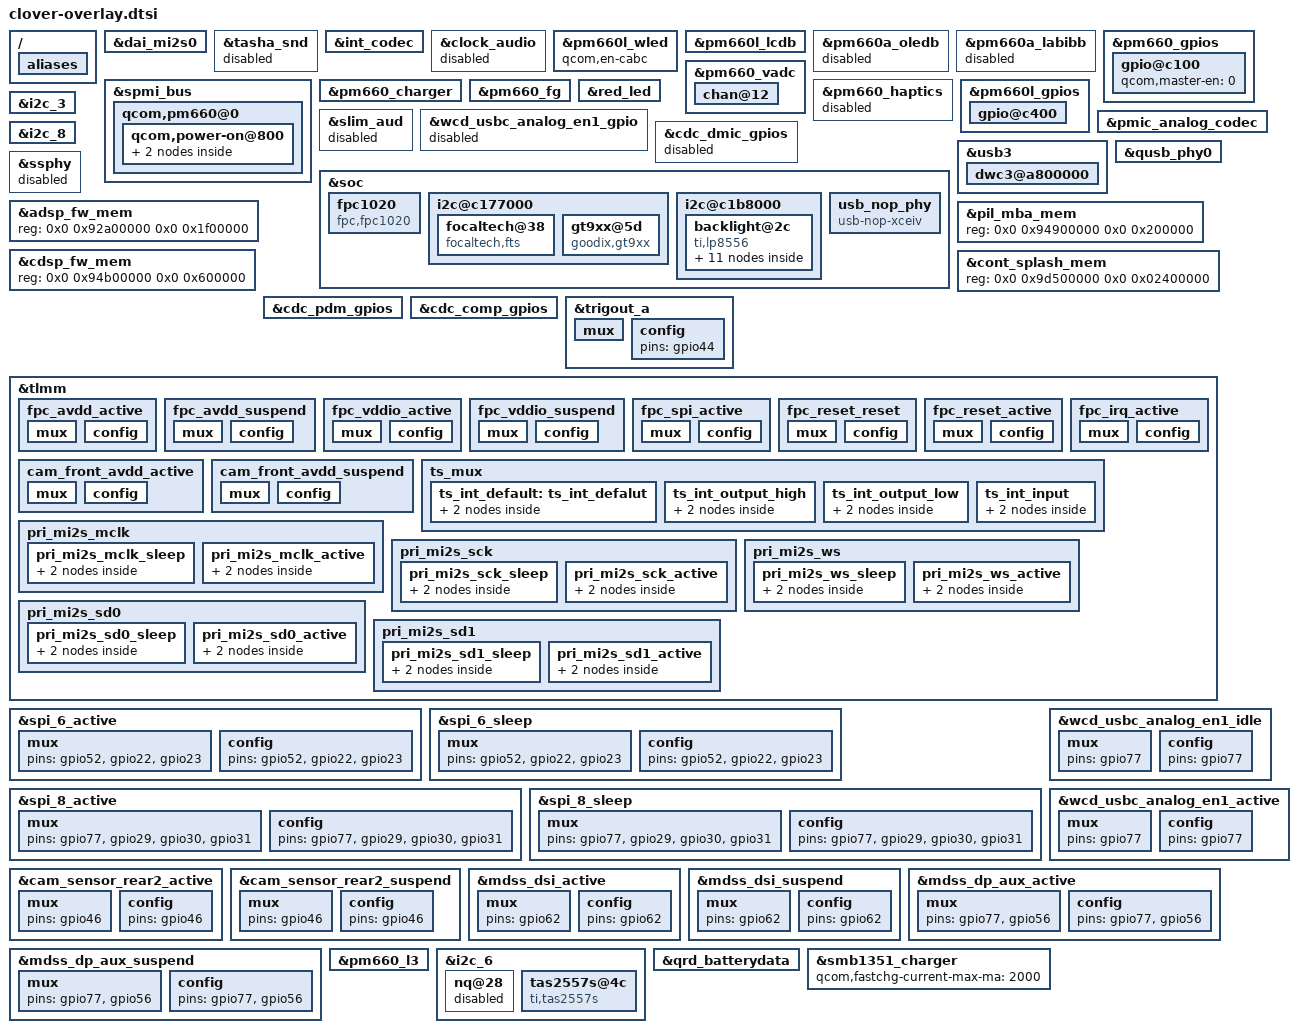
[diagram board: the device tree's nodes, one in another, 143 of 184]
&dai_mi2s0 {
	qcom,msm-mi2s-rx-lines = <1>;
	qcom,msm-mi2s-tx-lines = <2>;
	pinctrl-names = "default", "sleep";
	pinctrl-0 = <&pri_mi2s_mclk_active
		&pri_mi2s_sck_active
		&pri_mi2s_ws_active
		&pri_mi2s_sd0_active
		&pri_mi2s_sd1_active>;
	pinctrl-1 = <&pri_mi2s_mclk_sleep
		&pri_mi2s_sck_sleep
		&pri_mi2s_ws_sleep
		&pri_mi2s_sd0_sleep
		&pri_mi2s_sd1_sleep>;
};

&tasha_snd {
	status="disabled";
};
/*
&tavil_snd {
	status="disabled";
};
*/
&int_codec {
	/delete-property/ qcom,msm-micbias2-ext-cap;
	status="okay";
	qcom,wsa-disable;
	qcom,msm-mi2s-ext-mclk = <1>, <0>, <0>, <0>;
	qcom,msm-mbhc-gnd-swh = <0>;
	qcom,msm-micbias1-ext-cap;
	qcom,msm-hs-micbias-type = "internal";
	qcom,audio-routing =
		"RX_BIAS", "INT_MCLK0",
		"SPK_RX_BIAS", "INT_MCLK0",
		"INT_LDO_H", "INT_MCLK0",
		"RX_I2S_CLK", "INT_MCLK0",
		"TX_I2S_CLK", "INT_MCLK0",
		"MIC BIAS External", "Handset Mic",
		"MIC BIAS External2", "Headset Mic",
		"MIC BIAS Internal2", "Headset Mic",
		"MIC BIAS External", "Secondary Mic",
		"AMIC1", "MIC BIAS External",
		"AMIC2", "MIC BIAS External2",
		"AMIC2", "MIC BIAS Internal2",
		"AMIC3", "MIC BIAS External",
		"DMIC1", "MIC BIAS External",
		"MIC BIAS External", "Digital Mic1",
		"DMIC2", "MIC BIAS External",
		"MIC BIAS External", "Digital Mic2",
		"DMIC3", "MIC BIAS External",
		"MIC BIAS External", "Digital Mic3",
		"DMIC4", "MIC BIAS External",
		"MIC BIAS External", "Digital Mic4",
		"SpkrLeft IN", "SPK1 OUT",
		"SpkrRight IN", "SPK2 OUT",
		"PDM_IN_RX1", "PDM_OUT_RX1",
		"PDM_IN_RX2", "PDM_OUT_RX2",
		"PDM_IN_RX3", "PDM_OUT_RX3",
		"ADC1_IN", "ADC1_OUT",
		"ADC2_IN", "ADC2_OUT",
		"ADC3_IN", "ADC3_OUT";
};

&clock_audio {
	status="disabled";
};

&pm660l_wled {
	status = "okay";
};

&pm660l_lcdb {
	status = "okay";
};

&pm660a_oledb {
	status = "disabled";
};

&pm660a_labibb {
	status = "disable";
};

&spmi_bus {
	qcom,pm660@0 {
		qcom,power-on@800 {
			qcom,pon_1 {
				qcom,support-reset = <1>;
				qcom,s1-timer = <6720>;
				qcom,s2-timer = <1000>;
				qcom,s2-type = <7>;
			};
			qcom,pon_3 {
				qcom,pon-type = <3>;
				qcom,support-reset = <1>;
				qcom,pull-up = <1>;
				qcom,s1-timer = <3072>;
				qcom,s2-timer = <2000>;
				qcom,s2-type = <1>;
				qcom,use-bark;
			};
		};
	};
};

&pm660_gpios {
	gpio@c100 {
		status = "okay";
		qcom,master-en = <0>; /* DISABLE GPIO */
	};
};

&pm660_vadc {
	chan@12 {
		label = "gpio2_adc";
		reg = <0x12>;
		qcom,decimation = <2>;
		qcom,pre-div-channel-scaling = <0>;
		qcom,calibration-type = "absolute";
		qcom,scale-function = <0>; /*use default scale fuction, liyan 20180315*/
		qcom,hw-settle-time = <2>;
		qcom,fast-avg-setup = <0>;
	};
};

&pm660_charger {
	qcom,float-voltage-mv-ntc = <4100000>;
	qcom,fv-max-uv= <4400000>;
	qcom,thermal-mitigation
		= <2000000 2000000 2000000 1500000
			1000000 500000>;
};

&pm660_fg {
	qcom,max-voltage-uv = <4400000>;
	qcom,fg-cutoff-voltage = <3400>;
	qcom,fg-force-load-profile;
	qcom,fg-jeita-thresholds = <(-30) (-20) 70 75>;
};

&pm660_haptics {
	status="disabled";
};

&pm660l_gpios {
	gpio@c400 {
		status="okay";
	};
};

&red_led {
	qcom,max-current = <2>;
	qcom,start-idx = <1>;
	qcom,idx-len = <44>;
	qcom,duty-pcts =
		[00 01 05 0a 0f 14 19 1e 23 28 2d 32 37 3c 41 46 4b 50 55 5a 5f 64
		64 5f 5a 55 50 4b 46 41 3c 37 32 2d 28 23 1e 19 14 0f 0a 05 01 00];
	qcom,lut-flags = <27>;
	qcom,pause-lo = <0>;
	qcom,pause-hi = <0>;
	qcom,ramp-step-ms = <50>;
	qcom,turn-off-delay-ms = <500>;
	linux,default-trigger = "none";
};

&pm660l_wled {
	qcom,en-cabc;
};

&slim_aud {
	status="disabled";
};

&wcd_usbc_analog_en1_gpio {
	status="disabled";
};

&pmic_analog_codec {
	status="okay";
};

&cdc_dmic_gpios {
	status="disabled";
};

/ {
	aliases {
		/delete-property/ spi3;
		/delete-property/ spi4;
		/delete-property/ spi8;
	};
};

&i2c_3 {
	status="okay";
};

&i2c_8 {
	status="okay";
};

&soc {
	/delete-node/ spi_4;

	fpc1020 {
		status = "ok";
		compatible = "fpc,fpc1020";
		spi-max-frequency = <1000000>;
		input-device-name = "fpc1020";
		interrupt-parent = <&tlmm>;
		interrupts = <71 0x0>;
		fpc,gpio_rst    = <&tlmm 108 0>;
		fpc,gpio_irq    = <&tlmm 71 0>;

		clock-names = "iface_clk", "core_clk";
		clocks = <&clock_gcc GCC_BLSP2_AHB_CLK>,
			<&clock_gcc GCC_BLSP2_QUP3_SPI_APPS_CLK>;

		pinctrl-names = "fpc1020_avdd_active",
				"fpc1020_avdd_suspend",
				"fpc1020_vddio_active",
				"fpc1020_vddio_suspend",
				"fpc1020_spi_active",
				"fpc1020_reset_reset",
				"fpc1020_reset_active",
				"fpc1020_irq_active";

		pinctrl-0 = <&fpc_avdd_active>;
		pinctrl-1 = <&fpc_avdd_suspend>;
		pinctrl-2 = <&fpc_vddio_active>;
		pinctrl-3 = <&fpc_vddio_suspend>;
		pinctrl-4 = <&fpc_spi_active>;
		pinctrl-5 = <&fpc_reset_reset>;
		pinctrl-6 = <&fpc_reset_active>;
		pinctrl-7 = <&fpc_irq_active>;
	};

	i2c@c177000 {
		status = "ok";
		focaltech@38{
			compatible = "focaltech,fts";
			reg = <0x38>;
			interrupt-parent = <&tlmm>;
			interrupts = <67 0x2>;
			vdd-supply = <&pm660l_l3>;
			vcc_i2c-supply = <&pm660_l11>;
			focaltech,reset-gpio = <&tlmm 66 0x00>;
			focaltech,irq-gpio = <&tlmm 67 0x02>;
			focaltech,max-touch-number = <10>;
			focaltech,display-coords =  <0 0 1200 1920>;

			};
		gt9xx@5d{
			compatible = "goodix,gt9xx";
			reg = <0x5d>;
			interrupt-parent = <&tlmm>;
			interrupts = <67 0x2800>;
			pinctrl-names = "default", "int-output-low","int-output-high", "int-input";
			pinctrl-0 = <&ts_int_default>;
			pinctrl-1 = <&ts_int_output_low>;
			pinctrl-2 = <&ts_int_output_high>;
			pinctrl-3 = <&ts_int_input>;

			reset-gpios = <&tlmm 66 0x0>;
			irq-gpios = <&tlmm 67 0x2800>;
			irq-flags = <2>;

			vdd_ana-supply = <&pm660l_l3>;
			vcc_i2c-supply = <&pm660_l11>;

			touchscreen-max-id = <10>;
			touchscreen-size-x = <1200>;
			touchscreen-size-y = <1920>;
			touchscreen-max-w = <512>;
			touchscreen-max-p = <512>;
			touchscreen-key-map = <172>, <158>; /*KEY_HOMEPAGE=172, KEY_BACK=158，KEY_MENU=139*/

			goodix,slide-wakeup = <1>;
			goodix,type-a-report = <0>;
			goodix,driver-send-cfg = <1>;
			goodix,resume-in-workqueue = <0>;
			goodix,int-sync = <1>;
			goodix,swap-x2y = <0>;
			goodix,esd-protect = <1>;
			goodix,auto-update = <1>;
			goodix,auto-update-cfg = <1>;
			goodix,power-off-sleep = <0>;
			goodix,pen-suppress-finger = <0>;
			goodix,charger-cmd = <1>;
			goodix,cfg-group0 = [
                                54 B0 04 80 07 6A 35 10 11 CC
				32 0F 5A 32 2E 45 00 02 00 02
				11 12 09 14 19 1F 14 95 B5 DE
				1C 1E B0 15 33 22 00 22 44 1C
				FA FA F0 00 00 00 00 32 5A 00
				02 10 2F 8A D0 78 55 19 64 04
				A8 12 00 97 18 00 8F 1C 00 8A
				23 00 89 2D 00 89 1E 23 24 2F
				00 00 00 00 00 00 11 00 00 0C
				1E 0A 4A 04 F7 14 0A 0F 23 0F
				3C 32 0F 00 00 00 01 42 00 00
				01 14 00 01 02 03 04 05 06 07
				08 09 0A 0B 0C 0D 0E 0F 10 11
				12 13 14 15 16 17 18 19 1A FF
				FF FF 2A 29 28 27 26 25 24 23
				22 21 20 1F 1E 1D 1C 1B 19 18
				17 16 15 14 13 12 11 10 0F 0E
				0D 0C 0B 0A 09 08 07 06 05 04
				03 02 01 00 A3 01
				];
		};
	};

	i2c@c1b8000 {
		status = "ok";
		backlight@2c {
			compatible = "ti,lp8556";
			reg = <0x2c>;

			bl-name = "lcd-bl";

			rom_16h {
				rom-addr = /bits/ 8 <0x16>;
				rom-val = /bits/ 8 <0x0F>;
			};
			rom_01h {
				rom-addr = /bits/ 8 <0x01>;
				rom-val = /bits/ 8 <0x86>;
			};
			rom_00h {
				rom-addr = /bits/ 8 <0x00>;
				rom-val = /bits/ 8 <0x00>;
			};
			rom_01h_2 {
				rom-addr = /bits/ 8 <0x01>;
				rom-val = /bits/ 8 <0x87>;
			};
			rom_9Eh {
				rom-addr = /bits/ 8 <0x9E>;
				rom-val = /bits/ 8 <0x20>;
			};
			rom_A0h {
				rom-addr = /bits/ 8 <0xA0>;
				rom-val = /bits/ 8 <0x09>;
			};
			rom_A1h {
				rom-addr = /bits/ 8 <0xA1>;
				rom-val = /bits/ 8 <0x5F>;
			};
			rom_A3h {
				rom-addr = /bits/ 8 <0xA3>;
				rom-val = /bits/ 8 <0x0E>; /* Select brightness change transition duration 000 = 0 ms (immediate change)*/
			};
			rom_A5h {
				rom-addr = /bits/ 8 <0xA5>;
				rom-val = /bits/ 8 <0x24>;
			};
			rom_A9h {
				rom-addr = /bits/ 8 <0xA9>;
				rom-val = /bits/ 8 <0xA0>;
			};
			rom_AEh {
				rom-addr = /bits/ 8 <0xAE>;
				rom-val = /bits/ 8 <0x0E>;
			};
		};
	};

	usb_nop_phy: usb_nop_phy {
		compatible = "usb-nop-xceiv";
	};
};

&usb3 {
	dwc3@a800000 {
		usb-phy = <&qusb_phy0>, <&usb_nop_phy>;
		maximum-speed = "high-speed";
	};
};

&qusb_phy0 {
	qcom,tune2-efuse-correction = <4>;
	qcom,qusb-phy-init-seq = <0xf8 0x80
				0x53 0x84
				0x81 0x88
				0xcf 0x8c
				0x30 0x08
				0x79 0x0c
				0x21 0x10
				0x14 0x9c
				0x9f 0x1c
				0x00 0x18>;
};

&ssphy {
	status="disabled";
};

&adsp_fw_mem {
	reg = <0x0 0x92a00000 0x0 0x1f00000>;
};

&pil_mba_mem {
	reg = <0x0 0x94900000 0x0 0x200000>;
};

&cdsp_fw_mem {
	reg = <0x0 0x94b00000 0x0 0x600000>;
};

&cont_splash_mem {
	reg = <0x0 0x9d500000 0x0 0x02400000>;
};

&cdc_pdm_gpios {
	status = "okay";
};

&cdc_comp_gpios {
	status = "okay";
};

&trigout_a {
	mux {
		pins="gpio44";
		function="gpio";
	};
	config {
		pins="gpio44";
	};
};

&tlmm {
	/* fingerprint pin function */
	fpc_avdd_active: fpc_avdd_active {
		mux {
			pins = "gpio98";
			function = "gpio";
		};

		config {
			pins = "gpio98";
			driver-strength = <2>;
			bias-disable; /* No PULL */
			output-high;
		};
	};

	fpc_avdd_suspend: fpc_avdd_suspend {
		mux {
			pins = "gpio98";
			function = "gpio";
		};

		config {
			pins = "gpio98";
			driver-strength = <2>;
			bias-disable; /* No PULL */
			output-low;
		};
	};

	fpc_vddio_active: fpc_vddio_active {
		mux {
			pins = "gpio92";
			function = "gpio";
		};

		config {
			pins = "gpio92";
			driver-strength = <2>;
			bias-disable; /* No PULL */
			output-high;
		};
	};

	fpc_vddio_suspend: fpc_vddio_suspend {
		mux {
			pins = "gpio92";
			function = "gpio";
		};

		config {
			pins = "gpio92";
			driver-strength = <2>;
			bias-disable; /* No PULL */
			output-low;
		};
	};

	fpc_spi_active: fpc_spi_active {
		mux {
			pins = "gpio24", "gpio25", "gpio26", "gpio27";
			function = "blsp_spi7";
		};

		config {
			pins = "gpio24", "gpio25", "gpio26", "gpio27";
			drive-strength = <2>;
			bias-disable;
		};
	};

	fpc_reset_reset: fpc_reset_reset {
		mux {
			pins = "gpio108";
			function = "gpio";
		};

		config {
			pins = "gpio108";
			drive-strength = <2>;
			bias-disable;
			output-low;
		};
	};

	fpc_reset_active: fpc_reset_active {
		mux {
			pins = "gpio108";
			function = "gpio";
		};

		config {
			pins = "gpio108";
			drive-strength = <2>;
			bias-disable;
			output-high;
		};
	};

	fpc_irq_active: fpc_irq_active {
		mux {
			pins = "gpio71";
			function = "gpio";
		};

		config {
			pins = "gpio71";
			drive-strength = <2>;
			bias-disable;
			input-enable;
		};
	};

	/*front avdd en*/
	cam_front_avdd_active: cam_front_avdd_active {
		mux {
			pins = "gpio49";
			function = "gpio";
		};

		config {
			pins = "gpio49";
			bias-disable; /* No PULL */
			drive-strength = <2>; /* 2 MA */
		};
	};

	cam_front_avdd_suspend: cam_front_avdd_suspend {
		mux {
			pins = "gpio49";
			function = "gpio";
		};

		config {
			pins = "gpio49";
			bias-pull-down; /* PULL DOWN */
			drive-strength = <2>; /* 2 MA */
		};
	};
	/*front avdd en*/

	ts_mux {
		/delete-node/ ts_active;
		/delete-node/ ts_reset_suspend;
		/delete-node/ ts_int_suspend;

		/* add pingrp for touchscreen */
		ts_int_default: ts_int_defalut {
			mux {
				pins = "gpio67";
				function = "gpio";
			};

			config {
					pins = "gpio67";
					drive-strength = <16>;
					/*bias-pull-up;*/
					input-enable;
					bias-disable;
				};
		};

		ts_int_output_high: ts_int_output_high {
			mux {
				pins = "gpio67";
				function = "gpio";
			};

			config {
				pins = "gpio67";
				output-high;
			};
		};

		ts_int_output_low: ts_int_output_low {
			mux {
				pins = "gpio67";
				function = "gpio";
			};

			config {
				pins = "gpio67";
				output-low;
			};
		};

		ts_int_input: ts_int_input {
			mux {
				pins = "gpio67";
				function = "gpio";
			};

			config {
				pins = "gpio67";
				input-enable;
				bias-disable;
			};
		};
	};

	pri_mi2s_mclk {
		pri_mi2s_mclk_sleep: pri_mi2s_mclk_sleep {
			mux {
				pins = "gpio61";
				function = "gpio";
			};

			config {
				pins = "gpio61";
				drive-strength = <2>;   /* 2 mA */
				bias-pull-down;         /* PULL DOWN */
				input-enable;
			};
		};

		pri_mi2s_mclk_active: pri_mi2s_mclk_active {
			mux {
				pins = "gpio61";
				function = "pri_mi2s";
			};

			config {
				pins = "gpio61";
				drive-strength = <8>;   /* 8 mA */
				bias-disable;           /* NO PULL */
				output-high;
			};
		};
	};

	pri_mi2s_sck {
		pri_mi2s_sck_sleep: pri_mi2s_sck_sleep {
			mux {
				pins = "gpio12";
				function = "gpio";
			};

			config {
				pins = "gpio12";
				drive-strength = <2>;   /* 2 mA */
				bias-pull-down;         /* PULL DOWN */
				input-enable;
			};
		};

		pri_mi2s_sck_active: pri_mi2s_sck_active {
			mux {
				pins = "gpio12";
				function = "pri_mi2s";
			};

			config {
				pins = "gpio12";
				drive-strength = <8>;   /* 8 mA */
				bias-disable;           /* NO PULL */
				output-high;
			};
		};
	};

	pri_mi2s_ws {
		pri_mi2s_ws_sleep: pri_mi2s_ws_sleep {
			mux {
				pins = "gpio13";
				function = "gpio";
			};

			config {
				pins = "gpio13";
				drive-strength = <2>;   /* 2 mA */
				bias-pull-down;         /* PULL DOWN */
				input-enable;
			};
		};

		pri_mi2s_ws_active: pri_mi2s_ws_active {
			mux {
				pins = "gpio13";
				function = "pri_mi2s_ws";
			};

			config {
				pins = "gpio13";
				drive-strength = <8>;   /* 8 mA */
				bias-disable;           /* NO PULL */
				output-high;
			};
		};
	};

	pri_mi2s_sd0 {
		pri_mi2s_sd0_sleep: pri_mi2s_sd0_sleep {
			mux {
				pins = "gpio14";
				function = "gpio";
			};

			config {
				pins = "gpio14";
				drive-strength = <2>;   /* 2 mA */
				bias-pull-down;         /* PULL DOWN */
				input-enable;
			};
		};

		pri_mi2s_sd0_active: pri_mi2s_sd0_active {
			mux {
				pins = "gpio14";
				function = "pri_mi2s";
			};

			config {
				pins = "gpio14";
				drive-strength = <8>;   /* 8 mA */
				bias-disable;           /* NO PULL */
			};
		};
	};

	pri_mi2s_sd1 {
		pri_mi2s_sd1_sleep: pri_mi2s_sd1_sleep {
			mux {
				pins = "gpio15";
				function = "gpio";
			};

			config {
				pins = "gpio15";
				drive-strength = <2>;   /* 2 mA */
				bias-pull-down;         /* PULL DOWN */
				input-enable;
			};
		};

		pri_mi2s_sd1_active: pri_mi2s_sd1_active {
			mux {
				pins = "gpio15";
				function = "pri_mi2s";
			};

			config {
				pins = "gpio15";
				drive-strength = <8>;   /* 8 mA */
				bias-disable;           /* NO PULL */
			};
		};
	};
};

&spi_6_active {
	mux {
		pins="gpio52","gpio22","gpio23";
	};

	config {
		pins="gpio52","gpio22","gpio23";
	};
};

&spi_6_sleep {
	mux {
		pins="gpio52","gpio22","gpio23";
	};

	config {
		pins="gpio52","gpio22","gpio23";
	};
};

&spi_8_active {
	mux {
		pins="gpio77","gpio29","gpio30","gpio31";
	};

	config {
		pins="gpio77","gpio29","gpio30","gpio31";
	};
};

&spi_8_sleep {
	mux {
		pins="gpio77","gpio29","gpio30","gpio31";
	};

	config {
		pins="gpio77","gpio29","gpio30","gpio31";
	};
};

&wcd_usbc_analog_en1_idle {
	mux {
		pins="gpio77";
	};

	config {
		pins="gpio77";
	};
};

&wcd_usbc_analog_en1_active {
	mux {
		pins="gpio77";
	};

	config {
		pins="gpio77";
	};
};

&cam_sensor_rear2_active {
	mux {
		pins="gpio46";
	};

	config {
		pins="gpio46";
	};
};

&cam_sensor_rear2_suspend {
	mux {
		pins="gpio46";
	};

	config {
		pins="gpio46";
	};
};

&mdss_dsi_active {
	mux {
		pins="gpio62";
	};

	config {
		pins="gpio62";
	};
};

&mdss_dsi_suspend {
	mux {
		pins="gpio62";
	};

	config {
		pins="gpio62";
	};
};

&mdss_dp_aux_active {
	mux {
		pins="gpio77","gpio56";
	};

	config {
		pins="gpio77","gpio56";
	};
};

&mdss_dp_aux_suspend {
	mux {
		pins="gpio77","gpio56";
	};

	config {
		pins="gpio77","gpio56";
	};
};


&pm660_l3 {
	regulator-min-microvolt = <3000000>;
	regulator-max-microvolt = <3000000>;
};

&qusb_phy0 {
	qcom,qusb-phy-init-seq = <0xf8 0x80
				0x53 0x84
				0x81 0x88
				0xcf 0x8c
				0x30 0x08
				0x79 0x0c
				0x21 0x10
				0x14 0x9c
				0x9f 0x1c
				0x00 0x18>;
};

&i2c_6 {
	nq@28 {
		status="disabled";
	};

	tas2557s@4c {
		compatible = "ti,tas2557s";
		reg = <0x4c>;
		ti,reset-gpio-left = <&tlmm 80 0>;
		ti,reset-gpio-right = <&tlmm 48 0>;
		ti,irq-gpio-left = <&tlmm 28 0>;
		ti,irq-gpio-right = <&tlmm 55 0>;
		ti,left-channel = <0x4c>;
		ti,right-channel = <0x4e>;
		ti,echo-ref = <0>;   /* 0, left channel; 1, right channel; 2, both */
		ti,i2s-bits = <16>;   /* support 16, 24, 32 */
		ti,bypass-tmax = <0>;   /* 0, not bypass; 1, bypass */
		status = "ok";
	};
};

&tlmm {
	/delete-node/ pmx_ts_rst_active;
	/delete-node/ pmx_ts_rst_suspend;
};

&qrd_batterydata {
	 #include "clover/batterydata-zql5018-6000mah.dtsi"
	 #include "clover/batterydata-zql6019-8600mah.dtsi"
};

&pm660_fg {
	qcom,fg-jeita-thresholds = <(-30) (-20) 70 75>;
};

&smb1351_charger {
	qcom,fastchg-current-max-ma=<2000>;
};

#include "clover/clover-sdm660-mdss-panels.dtsi"
#include "clover/sdm660-camera-sensor-qrd.dtsi"
